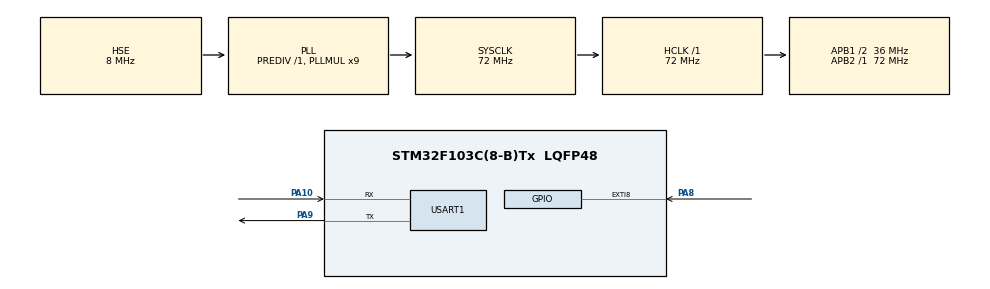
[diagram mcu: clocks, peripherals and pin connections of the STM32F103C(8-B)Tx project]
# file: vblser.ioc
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IWDG.Prescaler=IWDG_PRESCALER_8
Mcu.Family=STM32F1
Mcu.Name=STM32F103C(8-B)Tx
Mcu.Package=LQFP48
NVIC.EXTI9_5_IRQn=true\:0\:0\:false\:false\:true\:true\:true\:true
NVIC.PriorityGroup=NVIC_PRIORITYGROUP_4
NVIC.USART1_IRQn=true\:0\:0\:false\:false\:true\:true\:true\:true
PA10.Mode=Asynchronous
PA10.Signal=USART1_RX
PA13.Mode=Serial_Wire
PA13.Signal=SYS_JTMS-SWDIO
PA14.Mode=Serial_Wire
PA14.Signal=SYS_JTCK-SWCLK
PA8.Signal=GPXTI8
PA9.Mode=Asynchronous
PA9.Signal=USART1_TX
PD0-OSC_IN.Mode=HSE-External-Oscillator
PD0-OSC_IN.Signal=RCC_OSC_IN
PD1-OSC_OUT.Mode=HSE-External-Oscillator
PD1-OSC_OUT.Signal=RCC_OSC_OUT
ProjectManager.HeapSize=0x200
ProjectManager.StackSize=0x400
ProjectManager.TargetToolchain=STM32CubeIDE
RCC.AHBFreq_Value=72000000
RCC.APB1CLKDivider=RCC_HCLK_DIV2
RCC.APB1Freq_Value=36000000
RCC.APB1TimFreq_Value=72000000
RCC.APB2Freq_Value=72000000
RCC.APB2TimFreq_Value=72000000
RCC.HCLKFreq_Value=72000000
RCC.PLLMUL=RCC_PLL_MUL9
RCC.PLLSourceVirtual=RCC_PLLSOURCE_HSE
RCC.SYSCLKFreq_VALUE=72000000
RCC.SYSCLKSource=RCC_SYSCLKSOURCE_PLLCLK
RCC.USBFreq_Value=48000000
RCC.USBPrescaler=RCC_USBCLKSOURCE_PLL_DIV1_5
USART1.VirtualMode=VM_ASYNC
VP_IWDG_VS_IWDG.Mode=IWDG_Activate
board=custom

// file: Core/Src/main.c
/* USER CODE BEGIN Header */
/**
 ******************************************************************************
 * @file           : main.c
 * @brief          : Main program body
 ******************************************************************************
 * @attention
 *
 * Copyright (c) 2025 STMicroelectronics.
 * All rights reserved.
 *
 * This software is licensed under terms that can be found in the LICENSE file
 * in the root directory of this software component.
 * If no LICENSE file comes with this software, it is provided AS-IS.
 *
 ******************************************************************************
 */
/* USER CODE END Header */
#include "main.h"

/* USER CODE BEGIN Includes */
#include "string.h"
/* USER CODE END Includes */

IWDG_HandleTypeDef hiwdg;

UART_HandleTypeDef huart1;

/* USER CODE BEGIN PV */

header_t header;

volatile uint8_t got_freeze_tag;
volatile uint8_t got_send_tag;
volatile uint8_t got_reset_tag;
volatile uint8_t restart_tags;
volatile uint8_t tag_idx;
volatile tag_t tags[N_TAGS];

volatile uint8_t usart1_data;
volatile uint32_t usart1_timestamp;

volatile uint8_t vsync_irq;
volatile uint32_t vsync_timestamp;
volatile uint32_t prev_vsync_timestamp;

/* USER CODE END PV */

void SystemClock_Config(void);
static void MX_GPIO_Init(void);
static void MX_USART1_UART_Init(void);
static void MX_IWDG_Init(void);
/* USER CODE BEGIN PFP */

void HAL_UART_RxCpltCallback(UART_HandleTypeDef *huart) {
	if (huart->Instance == USART1) {
		HAL_UART_Receive_IT(&huart1, (uint8_t*) &usart1_data, 1);

		if (restart_tags) {
			restart_tags = 0;
			tag_idx = 0;
		}

		if (usart1_data == SERIAL_FREEZE) {
			got_freeze_tag = 1;
			return;
		} else if (usart1_data == SERIAL_DUMP) {
			got_send_tag = 1;
			return;
		} else if (usart1_data == SERIAL_RESET) {
			got_reset_tag = 1;
			return;
		}

		if (tag_idx < N_TAGS - 1) {
			tags[tag_idx].data = usart1_data;
			tags[tag_idx].timestamp = usart1_timestamp;
			tag_idx++;
		}
	}
}

void HAL_GPIO_EXTI_Callback(uint16_t GPIO_Pin) {
	vsync_irq = 1;
}

/* USER CODE END PFP */

/* USER CODE BEGIN 0 */

static void DWT_Init(void) {
	/* Enable TRC */
	CoreDebug->DEMCR |= CoreDebug_DEMCR_TRCENA_Msk;

	/* Reset the cycle counter */
	DWT->CYCCNT = 0;

	/* Enable the cycle counter */
	DWT->CTRL |= DWT_CTRL_CYCCNTENA_Msk;
}

/* USER CODE END 0 */

int main(void) {

	/* MCU Configuration--------------------------------------------------------*/

	/* Reset of all peripherals, Initializes the Flash interface and the Systick. */
	HAL_Init();

	/* USER CODE BEGIN Init */
	DWT_Init();

	/* USER CODE END Init */

	/* Configure the system clock */
	SystemClock_Config();

	/* Initialize all configured peripherals */
	MX_GPIO_Init();
	MX_USART1_UART_Init();
	MX_IWDG_Init();

	/* Infinite loop */
	/* USER CODE BEGIN WHILE */

	uint8_t buf[127] = { 0 };
	uint8_t bufcnt = 0;
	uint32_t count = 0;

	HAL_UART_Receive_IT(&huart1, (uint8_t*) &usart1_data, 1);

	while (1) {
		/* USER CODE END WHILE */

		/* USER CODE BEGIN 3 */

		if (vsync_irq) {
			vsync_irq = 0;
			count++;

			HAL_IWDG_Refresh(&hiwdg);
		}

		if (got_freeze_tag) {
			uint8_t tags_to_send = tag_idx;

			header.system_clock = SystemCoreClock;
			header.vsync_timestamp = vsync_timestamp;
			header.prev_vsync_timestamp = prev_vsync_timestamp;
			header.vsync_count = count;

			memcpy((void*) buf, (void*) &header, sizeof(header));
			memcpy((void*) (buf + sizeof(header)), (void*) tags,
					tags_to_send * sizeof(tag_t));

			bufcnt = sizeof(header) + sizeof(tag_t) * tags_to_send;
			HAL_UART_Transmit(&huart1, (uint8_t*) &bufcnt, 1, HAL_MAX_DELAY);

			restart_tags = 1;
			got_freeze_tag = 0;
		}

		if (got_send_tag) {
			HAL_UART_Transmit(&huart1, (uint8_t*) buf, bufcnt, HAL_MAX_DELAY);
			got_send_tag = 0;
		}

		if (got_reset_tag) {
			got_reset_tag = 0;
			count = 0;
			restart_tags = 1;
		}
	}

	/* USER CODE END 3 */
}

void SystemClock_Config(void) {
	RCC_OscInitTypeDef RCC_OscInitStruct = { 0 };
	RCC_ClkInitTypeDef RCC_ClkInitStruct = { 0 };

	/** Initializes the RCC Oscillators according to the specified parameters
	 * in the RCC_OscInitTypeDef structure.
	 */
	RCC_OscInitStruct.OscillatorType = RCC_OSCILLATORTYPE_LSI
			| RCC_OSCILLATORTYPE_HSE;
	RCC_OscInitStruct.HSEState = RCC_HSE_ON;
	RCC_OscInitStruct.HSEPredivValue = RCC_HSE_PREDIV_DIV1;
	RCC_OscInitStruct.HSIState = RCC_HSI_ON;
	RCC_OscInitStruct.LSIState = RCC_LSI_ON;
	RCC_OscInitStruct.PLL.PLLState = RCC_PLL_ON;
	RCC_OscInitStruct.PLL.PLLSource = RCC_PLLSOURCE_HSE;
	RCC_OscInitStruct.PLL.PLLMUL = RCC_PLL_MUL9;
	if (HAL_RCC_OscConfig(&RCC_OscInitStruct) != HAL_OK) {
		Error_Handler();
	}

	/** Initializes the CPU, AHB and APB buses clocks
	 */
	RCC_ClkInitStruct.ClockType = RCC_CLOCKTYPE_HCLK | RCC_CLOCKTYPE_SYSCLK
			| RCC_CLOCKTYPE_PCLK1 | RCC_CLOCKTYPE_PCLK2;
	RCC_ClkInitStruct.SYSCLKSource = RCC_SYSCLKSOURCE_PLLCLK;
	RCC_ClkInitStruct.AHBCLKDivider = RCC_SYSCLK_DIV1;
	RCC_ClkInitStruct.APB1CLKDivider = RCC_HCLK_DIV2;
	RCC_ClkInitStruct.APB2CLKDivider = RCC_HCLK_DIV1;

	if (HAL_RCC_ClockConfig(&RCC_ClkInitStruct, FLASH_LATENCY_2) != HAL_OK) {
		Error_Handler();
	}
}

static void MX_IWDG_Init(void) {

	hiwdg.Instance = IWDG;
	hiwdg.Init.Prescaler = IWDG_PRESCALER_8;
	hiwdg.Init.Reload = 4095;
	if (HAL_IWDG_Init(&hiwdg) != HAL_OK) {
		Error_Handler();
	}

}

static void MX_USART1_UART_Init(void) {

	huart1.Instance = USART1;
	huart1.Init.BaudRate = 115200;
	huart1.Init.WordLength = UART_WORDLENGTH_8B;
	huart1.Init.StopBits = UART_STOPBITS_1;
	huart1.Init.Parity = UART_PARITY_NONE;
	huart1.Init.Mode = UART_MODE_TX_RX;
	huart1.Init.HwFlowCtl = UART_HWCONTROL_NONE;
	huart1.Init.OverSampling = UART_OVERSAMPLING_16;
	if (HAL_UART_Init(&huart1) != HAL_OK) {
		Error_Handler();
	}

}

static void MX_GPIO_Init(void) {
	GPIO_InitTypeDef GPIO_InitStruct = { 0 };

	/* GPIO Ports Clock Enable */
	__HAL_RCC_GPIOD_CLK_ENABLE();
	__HAL_RCC_GPIOA_CLK_ENABLE();

	/*Configure GPIO pin : PA8 */
	GPIO_InitStruct.Pin = GPIO_PIN_8;
	GPIO_InitStruct.Mode = GPIO_MODE_IT_RISING;
	GPIO_InitStruct.Pull = GPIO_NOPULL;
	HAL_GPIO_Init(GPIOA, &GPIO_InitStruct);

	/* EXTI interrupt init*/
	HAL_NVIC_SetPriority(EXTI9_5_IRQn, 0, 0);
	HAL_NVIC_EnableIRQ(EXTI9_5_IRQn);

}

void Error_Handler(void) {
	__disable_irq();
	while (1) {
	}
}
